# EFM32GG11B520F2048GL120 register map
File version: 4.0.0
CPU: CM4 r0p1, little endian, MPU, FPU, 3 interrupt priority bits
Registers are 32-bit, read-write, reset 0x0 unless marked. A register's access mark holds for its fields unless they carry their own. Offsets are from the block's base; [hi:lo] are bit positions; {n}, {i} and the like mark numbered series.

## I2C0
Base 0x40089000
Same registers: I2C1 0x40089400, I2C2 0x40089800
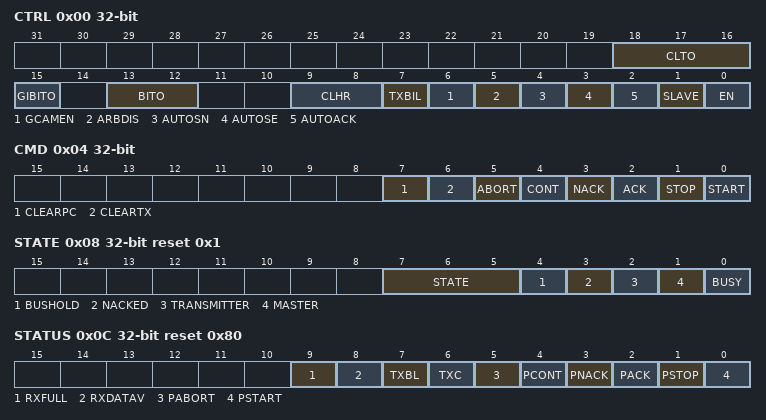
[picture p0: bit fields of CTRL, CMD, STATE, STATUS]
0x00 CTRL — Control Register
  [18:16] CLTO — Clock Low Timeout
    0=OFF (Timeout disabled); 1=40PCC (Timeout after 40 prescaled clock cycles. In standard mode at 100 kHz, this results in a 50us timeout.); 2=80PCC (Timeout after 80 prescaled clock cycles. In standard mode at 100 kHz, this results in a 100us timeout.); 3=160PCC (Timeout after 160 prescaled clock cycles. In standard mode at 100 kHz, this results in a 200us timeout.); 4=320PCC (Timeout after 320 prescaled clock cycles. In standard mode at 100 kHz, this results in a 400us timeout.); 5=1024PCC (Timeout after 1024 prescaled clock cycles. In standard mode at 100 kHz, this results in a 1280us timeout.)
  [15] GIBITO — Go Idle on Bus Idle Timeout
  [13:12] BITO — Bus Idle Timeout
    0=OFF (Timeout disabled); 1=40PCC (Timeout after 40 prescaled clock cycles. In standard mode at 100 kHz, this results in a 50us timeout.); 2=80PCC (Timeout after 80 prescaled clock cycles. In standard mode at 100 kHz, this results in a 100us timeout.); 3=160PCC (Timeout after 160 prescaled clock cycles. In standard mode at 100 kHz, this results in a 200us timeout.)
  [9:8] CLHR — Clock Low High Ratio
    0=STANDARD (The ratio between low period and high period counters (Nlow:Nhigh) is 4:4); 1=ASYMMETRIC (The ratio between low period and high period counters (Nlow:Nhigh) is 6:3); 2=FAST (The ratio between low period and high period counters (Nlow:Nhigh) is 11:6)
  [7] TXBIL — TX Buffer Interrupt Level
  [6] GCAMEN — General Call Address Match Enable
  [5] ARBDIS — Arbitration Disable
  [4] AUTOSN — Automatic STOP on NACK
  [3] AUTOSE — Automatic STOP When Empty
  [2] AUTOACK — Automatic Acknowledge
  [1] SLAVE — Addressable as Slave
  [0] EN — I2C Enable
0x04 CMD wo — Command Register
  [7] CLEARPC — Clear Pending Commands
  [6] CLEARTX
  [5] ABORT — Abort Transmission
  [4] CONT — Continue Transmission
  [3] NACK — Send NACK
  [2] ACK — Send ACK
  [1] STOP — Send Stop Condition
  [0] START — Send Start Condition
0x08 STATE ro reset 0x1
  [7:5] STATE — Transmission State
    0=IDLE (No transmission is being performed.); 1=WAIT (Waiting for idle. Will send a start condition as soon as the bus is idle.); 2=START (Start transmitted or received); 3=ADDR (Address transmitted or received); 4=ADDRACK (Address ack/nack transmitted or received); 5=DATA (Data transmitted or received); 6=DATAACK (Data ack/nack transmitted or received)
  [4] BUSHOLD — Bus Held
  [3] NACKED — Nack Received
  [2] TRANSMITTER
  [1] MASTER
  [0] BUSY — Bus Busy
0x0C STATUS ro reset 0x80
  [9] RXFULL — RX FIFO Full
  [8] RXDATAV — RX Data Valid
  [7] TXBL — TX Buffer Level
  [6] TXC — TX Complete
  [5] PABORT — Pending Abort
  [4] PCONT — Pending Continue
  [3] PNACK — Pending NACK
  [2] PACK — Pending ACK
  [1] PSTOP — Pending STOP
  [0] PSTART — Pending START
0x10 CLKDIV — Clock Division Register
  [8:0] DIV — Clock Divider
0x14 SADDR — Slave Address Register
  [7:1] ADDR — Slave Address
0x18 SADDRMASK — Slave Address Mask Register
  [7:1] MASK — Slave Address Mask
0x1C RXDATA ro read-has-side-effects — Receive Buffer Data Register
  [7:0] RXDATA
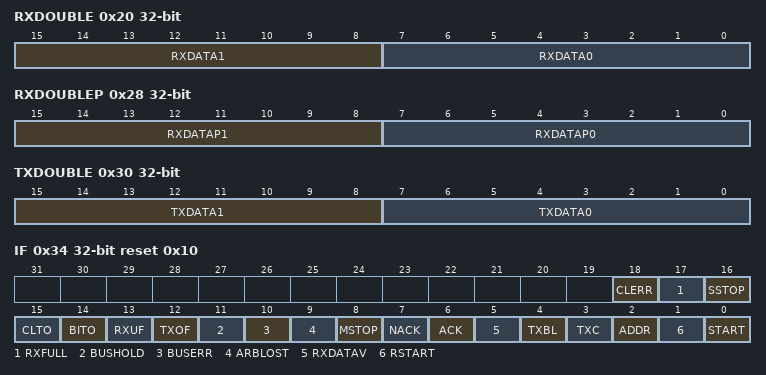
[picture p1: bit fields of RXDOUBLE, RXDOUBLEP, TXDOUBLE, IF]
0x20 RXDOUBLE ro read-has-side-effects — Receive Buffer Double Data Register
  [15:8] RXDATA1, [7:0] RXDATA0
0x24 RXDATAP ro — Receive Buffer Data Peek Register
  [7:0] RXDATAP — RX Data Peek
0x28 RXDOUBLEP ro — Receive Buffer Double Data Peek Register
  [15:8] RXDATAP1 — RX Data 1 Peek
  [7:0] RXDATAP0 — RX Data 0 Peek
0x2C TXDATA — Transmit Buffer Data Register
  [7:0] TXDATA
0x30 TXDOUBLE — Transmit Buffer Double Data Register
  [15:8] TXDATA1 — TX Data
  [7:0] TXDATA0 — TX Data
0x34 IF ro reset 0x10 — Interrupt Flag Register
  [18] CLERR — Clock Low Error Interrupt Flag
  [17] RXFULL — Receive Buffer Full Interrupt Flag
  [16] SSTOP — Slave STOP Condition Interrupt Flag
  [15] CLTO — Clock Low Timeout Interrupt Flag
  [14] BITO — Bus Idle Timeout Interrupt Flag
  [13] RXUF — Receive Buffer Underflow Interrupt Flag
  [12] TXOF — Transmit Buffer Overflow Interrupt Flag
  [11] BUSHOLD — Bus Held Interrupt Flag
  [10] BUSERR — Bus Error Interrupt Flag
  [9] ARBLOST — Arbitration Lost Interrupt Flag
  [8] MSTOP — Master STOP Condition Interrupt Flag
  [7] NACK — Not Acknowledge Received Interrupt Flag
  [6] ACK — Acknowledge Received Interrupt Flag
  [5] RXDATAV — Receive Data Valid Interrupt Flag
  [4] TXBL — Transmit Buffer Level Interrupt Flag
  [3] TXC — Transfer Completed Interrupt Flag
  [2] ADDR — Address Interrupt Flag
  [1] RSTART — Repeated START Condition Interrupt Flag
  [0] START — START Condition Interrupt Flag
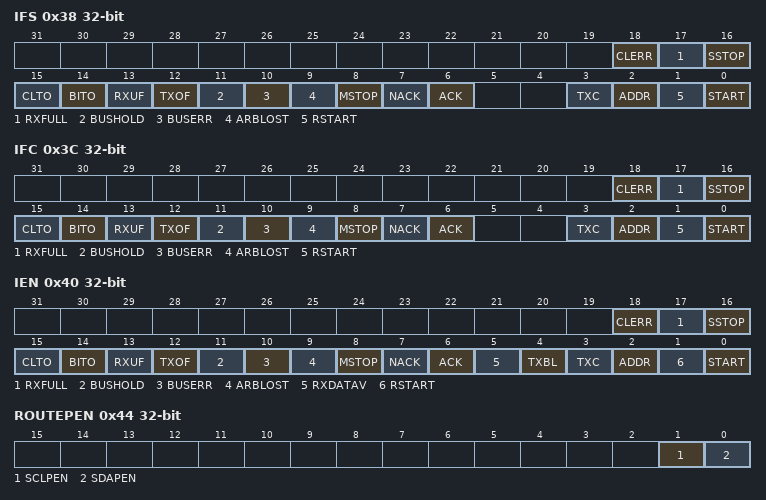
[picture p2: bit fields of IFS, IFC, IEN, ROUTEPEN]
0x38 IFS wo — Interrupt Flag Set Register
  [18] CLERR — Set CLERR Interrupt Flag
  [17] RXFULL — Set RXFULL Interrupt Flag
  [16] SSTOP — Set SSTOP Interrupt Flag
  [15] CLTO — Set CLTO Interrupt Flag
  [14] BITO — Set BITO Interrupt Flag
  [13] RXUF — Set RXUF Interrupt Flag
  [12] TXOF — Set TXOF Interrupt Flag
  [11] BUSHOLD — Set BUSHOLD Interrupt Flag
  [10] BUSERR — Set BUSERR Interrupt Flag
  [9] ARBLOST — Set ARBLOST Interrupt Flag
  [8] MSTOP — Set MSTOP Interrupt Flag
  [7] NACK — Set NACK Interrupt Flag
  [6] ACK — Set ACK Interrupt Flag
  [3] TXC — Set TXC Interrupt Flag
  [2] ADDR — Set ADDR Interrupt Flag
  [1] RSTART — Set RSTART Interrupt Flag
  [0] START — Set START Interrupt Flag
0x3C IFC wo — Interrupt Flag Clear Register
  [18] CLERR — Clear CLERR Interrupt Flag
  [17] RXFULL — Clear RXFULL Interrupt Flag
  [16] SSTOP — Clear SSTOP Interrupt Flag
  [15] CLTO — Clear CLTO Interrupt Flag
  [14] BITO — Clear BITO Interrupt Flag
  [13] RXUF — Clear RXUF Interrupt Flag
  [12] TXOF — Clear TXOF Interrupt Flag
  [11] BUSHOLD — Clear BUSHOLD Interrupt Flag
  [10] BUSERR — Clear BUSERR Interrupt Flag
  [9] ARBLOST — Clear ARBLOST Interrupt Flag
  [8] MSTOP — Clear MSTOP Interrupt Flag
  [7] NACK — Clear NACK Interrupt Flag
  [6] ACK — Clear ACK Interrupt Flag
  [3] TXC — Clear TXC Interrupt Flag
  [2] ADDR — Clear ADDR Interrupt Flag
  [1] RSTART — Clear RSTART Interrupt Flag
  [0] START — Clear START Interrupt Flag
0x40 IEN — Interrupt Enable Register
  [18] CLERR — CLERR Interrupt Enable
  [17] RXFULL — RXFULL Interrupt Enable
  [16] SSTOP — SSTOP Interrupt Enable
  [15] CLTO — CLTO Interrupt Enable
  [14] BITO — BITO Interrupt Enable
  [13] RXUF — RXUF Interrupt Enable
  [12] TXOF — TXOF Interrupt Enable
  [11] BUSHOLD — BUSHOLD Interrupt Enable
  [10] BUSERR — BUSERR Interrupt Enable
  [9] ARBLOST — ARBLOST Interrupt Enable
  [8] MSTOP — MSTOP Interrupt Enable
  [7] NACK — NACK Interrupt Enable
  [6] ACK — ACK Interrupt Enable
  [5] RXDATAV — RXDATAV Interrupt Enable
  [4] TXBL — TXBL Interrupt Enable
  [3] TXC — TXC Interrupt Enable
  [2] ADDR — ADDR Interrupt Enable
  [1] RSTART — RSTART Interrupt Enable
  [0] START — START Interrupt Enable
0x44 ROUTEPEN — I/O Routing Pin Enable Register
  [1] SCLPEN — SCL Pin Enable
  [0] SDAPEN — SDA Pin Enable
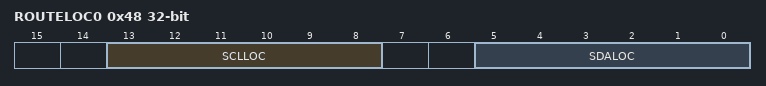
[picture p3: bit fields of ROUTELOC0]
0x48 ROUTELOC0 — I/O Routing Location Register
  [13:8] SCLLOC — I/O Location
    {v}=LOC{v} (Location {v}) (v=0..7)
  [5:0] SDALOC — I/O Location
    {v}=LOC{v} (Location {v}) (v=0..7)

## Notices in the file
# License
Copyright 2021 Silicon Laboratories Inc. www.silabs.com
SPDX-License-Identifier: Zlib
The licensor of this software is Silicon Laboratories Inc.
This software is provided 'as-is', without any express or implied
warranty. In no event will the authors be held liable for any damages
arising from the use of this software.
Permission is granted to anyone to use this software for any purpose,
including commercial applications, and to alter it and redistribute it
freely, subject to the following restrictions:
1. The origin of this software must not be misrepresented; you must not
claim that you wrote the original software. If you use this software
in a product, an acknowledgment in the product documentation would be
appreciated but is not required.
2. Altered source versions must be plainly marked as such, and must not be
misrepresented as being the original software.
3. This notice may not be removed or altered from any source distribution.
